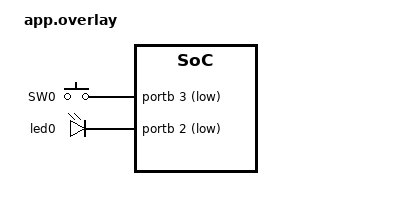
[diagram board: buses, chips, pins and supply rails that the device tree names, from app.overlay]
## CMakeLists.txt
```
cmake_minimum_required(VERSION 3.20.0)
find_package(Zephyr REQUIRED HINTS $ENV{ZEPHYR_BASE})
project(pic32cm_pl10_blinky_shell)
target_sources(app PRIVATE src/main.c src/led_ctrl.c src/pl10_adc.c src/cmd_parser.c src/fault.c src/diag.c src/button.c src/load.c src/standby.c src/sleeptest.c src/lpsleep.c)

# Declare the "cmd" console-command registry as an iterable ROM section (see
# app/src/cmd.h and app/cmd_sections.ld). SECTIONS (not ROM_SECTIONS) because
# ITERABLE_SECTION_ROM already places itself into the ROMABLE_REGION.
zephyr_linker_sources(SECTIONS cmd_sections.ld)
```

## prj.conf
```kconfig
CONFIG_GPIO=y
CONFIG_SERIAL=y
CONFIG_CONSOLE=y
CONFIG_UART_CONSOLE=y
CONFIG_LOG=n
CONFIG_REBOOT=y

# We print the boot banner ourselves from cmd_parser.c (with a leading newline,
# so it starts on a fresh line even after a fault-reboot's non-newline-
# terminated dump). Disable Zephyr's built-in banner to avoid printing it twice.
CONFIG_BOOT_BANNER=n

# Lightweight custom command parser instead of the Zephyr shell subsystem: the shell
# took up 39%/38% of RAM/Flash for four trivial LED commands - disproportionate on an
# 8 KB-RAM device. console_getchar() is Zephyr's built-in pull-style, character-by-
# character input API; the app's own cmd_parser.c builds line editing and bash-style
# history recall on top of it (console_getline()'s line-buffered mode can't do
# history - Zephyr's console driver silently drops Up/Down arrow escape sequences).
CONFIG_CONSOLE_SUBSYS=y
CONFIG_CONSOLE_GETCHAR=y

# Fixed kernel baseline trimmed too (ISR stack 2048 B default, main stack 1024 B
# default). ISR_STACK_SIZE is shared globally by ALL interrupts + kernel init -
# riskier to cut than the shell stack, since an overflow is more likely to silently
# corrupt memory than fault cleanly. Verified stable via a pyserial stress test
# (10 ms blink timer running concurrently with 15 rapid "help" calls, the app's
# deepest printk call path) - see RUNBOOK.md Step 7 for details. RAM saved: 52.25% ->
# 33.50%.
CONFIG_ISR_STACK_SIZE=1024
CONFIG_MAIN_STACK_SIZE=512

# Thread introspection for the "threads" console command (k_thread_foreach +
# live stack usage). THREAD_MONITOR maintains the runtime thread list;
# THREAD_NAME stores names (MAX_NAME_LEN trimmed to fit "adc_stream_tid");
# THREAD_STACK_INFO + INIT_STACKS give an accurate used-stack count (INIT_STACKS
# fills each stack with a pattern at init so unused bytes can be counted).
CONFIG_THREAD_MONITOR=y
CONFIG_THREAD_NAME=y
CONFIG_THREAD_MAX_NAME_LEN=16
CONFIG_THREAD_STACK_INFO=y
CONFIG_INIT_STACKS=y

# Software stack-overflow detection. This Cortex-M0+ has no MPU, so the
# hardware option (CONFIG_HW_STACK_PROTECTION) is unavailable; the sentinel is
# the software fallback: a magic value at the bottom of each thread stack,
# checked at every context switch and on ISRs. If a thread overflows past it,
# the kernel raises a fatal error (K_ERR_STACK_CHK_FAIL, reason 2) instead of
# silently corrupting memory. NOTE: the kernel's own thread-naming line goes
# through LOG_ERR and is compiled out by CONFIG_LOG=n above - src/fault.c
# overrides k_sys_fatal_error_handler() to printk the reason + offending thread
# name so the overflow is attributable. Costs 4 B/stack + the periodic checks.
CONFIG_STACK_SENTINEL=y

# Recover automatically from a fatal error (stack overflow, HardFault from a
# bad "mem" address, ...): the kernel prints the full fault dump as usual and
# then reboots, instead of halting forever waiting for a manual reset. Trade-
# off: you can't inspect the halted state with a debugger after the fact - but
# the register/reason dump is already printed before the reset.
CONFIG_RESET_ON_FATAL_ERROR=y

# NOTE on Power Management: the "standby <s>" command (app/src/standby.c) drops
# the SoC into real ~2 uA Standby with direct-register access and REBOOTS on wake -
# it deliberately does NOT use Zephyr's PM subsystem (CONFIG_PM). Mainline Zephyr
# has no PM/power-domain driver for the PL10, and supplying the hooks ourselves
# gave a Standby that reached 2 uA but left the kernel tick dead afterwards (gating
# OSCHF kills the RTC compare the tickless low-power path relies on). So CONFIG_PM
# is intentionally absent; see the header comment in standby.c for the full story.
```

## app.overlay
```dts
/*
 * Application devicetree overlay for the PIC32CM PL10 Curiosity Nano.
 *
 * Zephyr's board support defines only led0 (PB2), not the on-board user switch.
 * The PIC32CM PL10 Curiosity Nano User Guide (DS50004003, section 4.2
 * "Mechanical Switch") puts SW0 on PB03: pressing it pulls the pin to GND, and
 * there is no external pull-up, so it is active-low and needs the MCU's internal
 * pull-up enabled. This overlay adds it as a gpio-keys node with an `sw0` alias;
 * button.c reads it via GPIO_DT_SPEC_GET (no CONFIG_INPUT needed - the node is
 * just data we read with the GPIO API).
 */
#include <zephyr/dt-bindings/gpio/gpio.h>
#include <zephyr/dt-bindings/input/input-event-codes.h>

/ {
	buttons {
		compatible = "gpio-keys";

		sw0: button_0 {
			gpios = <&portb 3 (GPIO_ACTIVE_LOW | GPIO_PULL_UP)>;
			label = "SW0";
			zephyr,code = <INPUT_KEY_0>;
		};
	};

	aliases {
		sw0 = &sw0;
	};
};

/*
 * Fix the LED0 polarity. The board devicetree declares led0 as GPIO_ACTIVE_HIGH,
 * but the on-board LED is wired active-low - the User Guide (section 4.1 "LED")
 * states "Driving the connected I/O line to GND will activate the LED". With the
 * wrong flag every led_ctrl_*() call is inverted (`led on` drives the pin high =
 * LED off), and - importantly for power - `led_ctrl_off()` drove the pin LOW,
 * turning the LED physically ON and sinking ~1 mA through it during `standby`.
 * Overriding the flag here (rather than editing the pinned board file) makes
 * on/off correct and lets the LED actually go dark in Standby.
 */
&led0 {
	gpios = <&portb 2 GPIO_ACTIVE_LOW>;
};
```

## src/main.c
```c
#include "led_ctrl.h"

/*
 * The application is built from self-contained modules that each start their
 * own thread (led_ctrl.c's blink thread, cmd_parser.c's command thread,
 * pl10_adc.c's stream thread). main() only wires up startup policy: bring the
 * LED up and set its default state.
 */
int main(void)
{
    if (led_ctrl_init() != 0) {
        return 0;
    }
    led_ctrl_blink(500);
    return 0;
}
```

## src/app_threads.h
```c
#ifndef APP_THREADS_H_
#define APP_THREADS_H_

/*
 * Central budget/priority table for the application threads.
 *
 * The threads themselves are still defined (K_THREAD_DEFINE) in the module
 * that owns their state - led_ctrl.c, pl10_adc.c, cmd_parser.c - so each
 * module stays self-contained. Only their stack sizes and priorities live
 * here, so every thread budget can be seen and tuned in one place instead of
 * hunting through the modules. For a live view of actual stack usage, run the
 * "threads" console command (see cmd_parser.c).
 */

/*
 * Stack sizes are set with headroom over the measured high-water mark (run
 * the "threads" command to see live usage). The initial 256/320 B for the
 * blink/ADC threads turned out to read 100%/97% used - bumped to 512 so
 * there's real margin, since a Cortex-M0+ overflow corrupts silently (no MPU
 * / no stack sentinel here). Re-check with "threads" after touching a thread's
 * call path (e.g. a deeper driver call, printf format).
 */
#define BLINK_THREAD_STACK_SIZE       352
#define BLINK_THREAD_PRIORITY         7

#define ADC_STREAM_THREAD_STACK_SIZE  352
#define ADC_STREAM_THREAD_PRIORITY    7

#define CMD_THREAD_STACK_SIZE         640
#define CMD_THREAD_PRIORITY           7

#define BUTTON_THREAD_STACK_SIZE      384
#define BUTTON_THREAD_PRIORITY        7

/*
 * The CPU-load generator (load.c, the "load" command). Priority is one *below*
 * the app threads above so it only burns time that would otherwise be idle:
 * the console/blink/ADC/button threads (priority 7) always preempt it, so they
 * stay responsive while the core is held busy. Its stack is tiny - the thread
 * only runs an arithmetic loop and a semaphore take, no printf/driver calls -
 * but re-check with the "threads" command after any change.
 */
#define LOAD_THREAD_STACK_SIZE        320
#define LOAD_THREAD_PRIORITY          8

#endif /* APP_THREADS_H_ */
```

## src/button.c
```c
/*
 * button.c - read the on-board user switch SW0 and expose it as the `button`
 * console command.
 *
 * SW0 is on PB03 (PIC32CM PL10 Curiosity Nano User Guide DS50004003, section 4.2
 * "Mechanical Switch"). Pressing it pulls PB03 to GND, and the board has no
 * external pull-up, so the pin is configured active-low with the MCU's internal
 * pull-up enabled - both flags come from the devicetree node in app/app.overlay
 * (Zephyr's board support defines only led0, not the switch). Because
 * gpio_pin_get_dt() returns the *logical* level, GPIO_ACTIVE_LOW is handled for
 * us: 1 means pressed.
 *
 * Two ways to observe it: the `button` console command reads the current state
 * on demand, and a small background thread (button_tid) watches for edges and
 * prints a message when the button is pressed or released - asynchronously,
 * like pl10_adc.c's stream. GPIO pin interrupts aren't an option here: the
 * PL10's pin-interrupt path needs the EIC (CONFIG_INTC_MCHP_EIC_G1), and this
 * Zephyr revision has no EIC devicetree node for the PL10, so
 * gpio_pin_interrupt_configure() returns -ENOTSUP. Polling every 50 ms is well
 * within a human press and also debounces the switch (contact bounce is far
 * shorter than the poll interval).
 *
 * Self-registered via CMD_REGISTER (like diag.c); the pin is configured lazily
 * on first use (mirrors pl10_adc.c's ensure_adc_ready) so main.c stays
 * untouched.
 */
#include <zephyr/kernel.h>
#include <zephyr/drivers/gpio.h>
#include <errno.h>

#include "app_threads.h"
#include "cmd.h"

#define SW0_NODE DT_ALIAS(sw0)
static const struct gpio_dt_spec sw0 = GPIO_DT_SPEC_GET(SW0_NODE, gpios);

static bool sw0_ready;

static int ensure_sw0_ready(void)
{
    if (sw0_ready) {
        return 0;
    }
    if (!gpio_is_ready_dt(&sw0)) {
        return -ENODEV;
    }

    /* GPIO_INPUT combines with the node's dt_flags (GPIO_ACTIVE_LOW |
     * GPIO_PULL_UP), so the internal pull-up is enabled here. */
    int ret = gpio_pin_configure_dt(&sw0, GPIO_INPUT);
    if (ret != 0) {
        return ret;
    }

    sw0_ready = true;
    return 0;
}

static void button_cmd(int argc, char **argv)
{
    ARG_UNUSED(argc);
    ARG_UNUSED(argv);

    if (ensure_sw0_ready() != 0) {
        printk("button: not available\n");
        return;
    }

    int val = gpio_pin_get_dt(&sw0);
    if (val < 0) {
        printk("button: read error %d\n", val);
        return;
    }

    printk("button: %s\n", val ? "pressed" : "released");
}
CMD_REGISTER(button, "button", button_cmd, "button          - read the SW0 user button");

/* --- background press/release notifier ---------------------------------- */

#define BUTTON_POLL_MS 50

static void button_thread_entry(void *p1, void *p2, void *p3)
{
    ARG_UNUSED(p1);
    ARG_UNUSED(p2);
    ARG_UNUSED(p3);

    if (ensure_sw0_ready() != 0) {
        return; /* pin unavailable - nothing to watch */
    }

    /* Seed with the current level so we only report actual changes. */
    int prev = gpio_pin_get_dt(&sw0);

    while (1) {
        k_sleep(K_MSEC(BUTTON_POLL_MS));

        int cur = gpio_pin_get_dt(&sw0);
        if (cur < 0 || cur == prev) {
            continue;
        }

        printk("button: %s\n", cur ? "pressed" : "released");
        prev = cur;
    }
}
K_THREAD_DEFINE(button_tid, BUTTON_THREAD_STACK_SIZE, button_thread_entry, NULL, NULL, NULL,
        BUTTON_THREAD_PRIORITY, 0, 0);
```

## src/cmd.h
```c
#ifndef CMD_H_
#define CMD_H_

#include <zephyr/sys/iterable_sections.h>

/*
 * Console command registry. Each feature module registers its own top-level
 * command with CMD_REGISTER(); the parser (cmd_parser.c) only tokenizes the
 * line, looks up argv[0] in this registry and dispatches - it has no knowledge
 * of led/adc/etc. The registration table lives in a custom iterable ROM
 * section ("cmd"), built at link time, so it costs ~0 RAM (same mechanism as
 * Zephyr's SHELL_CMD_REGISTER, without the shell subsystem's overhead). The
 * linker section is declared in app/cmd_sections.ld (wired in via
 * zephyr_linker_sources() in app/CMakeLists.txt).
 */

/* Handler for one command. argv[0] is the command name; argv[1..argc-1] are
 * its arguments. Handlers print their own output/usage (hence void). */
typedef void (*cmd_fn_t)(int argc, char **argv);

struct cmd {
	const char *name; /* first token to match, e.g. "led" */
	cmd_fn_t fn;      /* dispatched handler */
	const char *help; /* one-line help, printed by the "help" command */
};

/*
 * Register a command. `id` must be unique within its source file (it forms the
 * variable name). `const` is mandatory: it places the entry in the ROM "cmd"
 * section rather than RAM. The entry is not referenced by name anywhere, so the
 * KEEP() in the linker fragment is what stops the linker from garbage-collecting
 * it.
 */
#define CMD_REGISTER(id, name_, fn_, help_)                       \
	static const STRUCT_SECTION_ITERABLE(cmd, _cmd_##id) = {  \
		.name = (name_),                                  \
		.fn = (fn_),                                      \
		.help = (help_),                                  \
	}

#endif /* CMD_H_ */
```

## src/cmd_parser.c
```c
#include <zephyr/kernel.h>
#include <zephyr/console/console.h>
#include <zephyr/version.h>
#include <ctype.h>
#include <stdbool.h>
#include <string.h>

#include "app_threads.h"
#include "cmd.h"

/*
 * Generic console front-end: a hand-rolled line editor (with bash-style Up/Down
 * history) over console_getchar(), plus a tokenizer that dispatches each line
 * to the command registry (cmd.h). This module knows nothing about led/adc/etc.
 * - every command lives in its owning module and self-registers via
 * CMD_REGISTER(); adding a command never touches this file. Only "help" is
 * built in here, since it is intrinsic to the registry.
 */

/*
 * We print the boot banner ourselves (CONFIG_BOOT_BANNER=n) so it can start
 * with a leading newline - Zephyr's own banner has no leading '\n', so after
 * a fault-triggered reboot it glued onto the tail of the (non-newline-
 * terminated) fault dump. Version string derived exactly as Zephyr's
 * boot_banner.c does. */
#if defined(BUILD_VERSION) && !IS_EMPTY(BUILD_VERSION)
#define ZEPHYR_VERSION_STR STRINGIFY(BUILD_VERSION)
#else
#define ZEPHYR_VERSION_STR KERNEL_VERSION_STRING
#endif

#define PROMPT "pl10:~$ "

#define CMD_LINE_MAX_LEN 32
#define CMD_HISTORY_DEPTH 5
#define CMD_MAX_ARGS 4 /* deepest: "adc stream start" / "mem <addr> <n>" = 3 */

#define KEY_BS 0x08
#define KEY_DEL 0x7f
#define KEY_ESC 0x1b
#define KEY_CSI '['
#define KEY_UP 'A'
#define KEY_DOWN 'B'

/* Split `line` into argv[] in place (spaces overwritten with '\0'). Returns
 * argc; extra tokens beyond `max` are left attached to the last argv entry. */
static int tokenize(char *line, char **argv, int max)
{
    int argc = 0;

    while (*line != '\0' && argc < max) {
        while (*line == ' ') {
            *line++ = '\0';
        }
        if (*line == '\0') {
            break;
        }
        argv[argc++] = line;
        while (*line != '\0' && *line != ' ') {
            line++;
        }
    }
    return argc;
}

static void handle_line(char *line)
{
    char *argv[CMD_MAX_ARGS];
    int argc = tokenize(line, argv, CMD_MAX_ARGS);

    if (argc == 0) {
        return; /* empty line */
    }

    STRUCT_SECTION_FOREACH(cmd, c) {
        if (strcmp(argv[0], c->name) == 0) {
            c->fn(argc, argv);
            return;
        }
    }
    printk("unknown command: %s\n", argv[0]);
}

/* "help" is built in here: it iterates the command registry and prints each
 * entry's one-line help. Registration order is link order (not sorted). */
static void help_cmd(int argc, char **argv)
{
    ARG_UNUSED(argc);
    ARG_UNUSED(argv);

    printk("Available commands:\n");
    STRUCT_SECTION_FOREACH(cmd, c) {
        printk("  %s\n", c->help);
    }
    printk("  (Up/Down arrow recalls the last %u commands)\n", CMD_HISTORY_DEPTH);
}
CMD_REGISTER(help, "help", help_cmd, "help            - show this help");

/* Ring buffer of the last CMD_HISTORY_DEPTH submitted lines, oldest first. */
static char cmd_history[CMD_HISTORY_DEPTH][CMD_LINE_MAX_LEN];
static uint8_t cmd_history_count;
static uint8_t cmd_history_next;

/* Map a chronological position (0 = oldest kept, cmd_history_count - 1 =
 * newest) to its physical ring-buffer slot. */
static uint8_t cmd_history_index(uint8_t pos)
{
    uint8_t start = (cmd_history_count == CMD_HISTORY_DEPTH) ? cmd_history_next : 0;
    return (start + pos) % CMD_HISTORY_DEPTH;
}

static void cmd_history_add(const char *line)
{
    if (*line == '\0') {
        return;
    }

    strncpy(cmd_history[cmd_history_next], line, CMD_LINE_MAX_LEN - 1);
    cmd_history[cmd_history_next][CMD_LINE_MAX_LEN - 1] = '\0';

    cmd_history_next = (cmd_history_next + 1) % CMD_HISTORY_DEPTH;
    if (cmd_history_count < CMD_HISTORY_DEPTH) {
        cmd_history_count++;
    }
}

/*
 * printk() and console_putchar() are two independent output paths on top of
 * the same UART (printk goes straight through uart_console.c's synchronous
 * uart_poll_out(); console_putchar() goes through console_getchar()'s own
 * buffered, interrupt-driven tty layer). Mixing them reorders/drops bytes on
 * the wire, so every echo/redraw byte here goes through printk("%c", ...)
 * instead of console_putchar() - one single output path throughout.
 */
static void echo_char(char c)
{
    printk("%c", c);
}

static void echo_backspace(void)
{
    printk("\b \b");
}

/* Erase `len` already-echoed characters left of the cursor and reprint
 * `text` (`len_new` chars) in their place - works on any plain terminal,
 * no ANSI cursor-positioning required. */
static void redraw_line(size_t len, const char *text, size_t len_new)
{
    for (size_t i = 0; i < len; i++) {
        echo_backspace();
    }
    for (size_t i = 0; i < len_new; i++) {
        echo_char(text[i]);
    }
}

/* Hand-rolled line editor: console_getline() has no Up/Down history recall
 * (Zephyr's console driver silently drops those escape sequences - see
 * conversation history), so this reads character-by-character via
 * console_getchar() instead and implements just enough editing for this
 * app: end-of-line backspace, and bash-style history browsing. No mid-line
 * cursor movement (Left/Right arrows) - out of scope for this minimal
 * parser, same reasoning that kept the Zephyr shell out of this project.
 */
static size_t cmd_read_line(char *buf, size_t buf_size)
{
    /* Persists across calls: a "\r\n" pair spans two console_getchar() calls
     * that can land in two different cmd_read_line() invocations (the '\r'
     * ends this line; the '\n' arrives right at the start of the next
     * read). Remembering the last byte lets that trailing '\n' be swallowed
     * instead of being misread as an Enter on an empty line - same trick
     * Zephyr's own uart_console_isr() uses for CONFIG_CONSOLE_GETLINE. */
    static uint8_t last_char;

    size_t len = 0;
    uint8_t history_pos = cmd_history_count; /* one past newest = "not browsing" */

    buf[0] = '\0';

    while (1) {
        int c = console_getchar();

        if (c < 0) {
            continue;
        }

        if (c == '\n' && last_char == '\r') {
            last_char = (uint8_t)c;
            continue;
        }
        last_char = (uint8_t)c;

        if (c == '\r' || c == '\n') {
            printk("\n");
            buf[len] = '\0';
            return len;
        }

        if (c == KEY_BS || c == KEY_DEL) {
            if (len > 0) {
                len--;
                echo_backspace();
            }
            continue;
        }

        if (c == KEY_ESC) {
            if (console_getchar() != KEY_CSI) {
                continue;
            }
            int key = console_getchar();

            if (key != KEY_UP && key != KEY_DOWN) {
                continue; /* unsupported escape sequence - ignore */
            }

            uint8_t new_pos = history_pos;
            if (key == KEY_UP && history_pos > 0) {
                new_pos = history_pos - 1;
            } else if (key == KEY_DOWN && history_pos < cmd_history_count) {
                new_pos = history_pos + 1;
            }
            if (new_pos == history_pos) {
                continue;
            }
            history_pos = new_pos;

            size_t old_len = len;
            if (history_pos == cmd_history_count) {
                len = 0;
            } else {
                len = strlen(cmd_history[cmd_history_index(history_pos)]);
                memcpy(buf, cmd_history[cmd_history_index(history_pos)], len);
            }
            buf[len] = '\0';
            redraw_line(old_len, buf, len);
            continue;
        }

        if (isprint(c) != 0 && len + 1 < buf_size) {
            buf[len++] = (char)c;
            echo_char((char)c);
        }
    }
}

static void cmd_thread_entry(void *p1, void *p2, void *p3)
{
    console_init();

    static char line[CMD_LINE_MAX_LEN];

    /* Leading '\n' (printk emits it as CR+LF) so the banner always starts on
     * a fresh line, even right after a non-newline-terminated fault dump. */
    printk("\n*** Booting Zephyr OS build " ZEPHYR_VERSION_STR " ***\n"
           "PIC32CM PL10 Blinky - built " __DATE__ " " __TIME__ "\n");
    printk(PROMPT);
    while (1) {
        cmd_read_line(line, sizeof(line));
        cmd_history_add(line);
        handle_line(line);
        printk(PROMPT);
    }
}
K_THREAD_DEFINE(cmd_tid, CMD_THREAD_STACK_SIZE, cmd_thread_entry, NULL, NULL, NULL,
        CMD_THREAD_PRIORITY, 0, 0);
```

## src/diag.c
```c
/*
 * diag.c - system / diagnostic console commands: reset, threads, mem.
 *
 * These are not tied to any feature peripheral, so they live here (rather than
 * in the parser) and self-register with the command registry (cmd.h), keeping
 * cmd_parser.c free of any command-specific knowledge.
 */
#include <zephyr/kernel.h>
#include <zephyr/sys/reboot.h>
#include <stdlib.h>

#include "cmd.h"

static void reset_cmd(int argc, char **argv)
{
    ARG_UNUSED(argc);
    ARG_UNUSED(argv);

    printk("resetting...\n");
    sys_reboot(SYS_REBOOT_COLD);
}
CMD_REGISTER(reset, "reset", reset_cmd, "reset           - reboot the board");

/* k_thread_foreach() callback: print one thread's name, priority, and live
 * stack usage. Needs CONFIG_THREAD_MONITOR (thread list), THREAD_NAME
 * (names), THREAD_STACK_INFO + INIT_STACKS (accurate used-stack count) -
 * see prj.conf. */
static void thread_info_cb(const struct k_thread *thread, void *user_data)
{
    ARG_UNUSED(user_data);

    size_t unused = 0;
    (void)k_thread_stack_space_get(thread, &unused);

    size_t total = thread->stack_info.size;
    const char *name = k_thread_name_get((k_tid_t)thread);

    printk("  %-14s prio %2d  stack %u/%u B\n",
           (name != NULL && name[0] != '\0') ? name : "?",
           k_thread_priority_get((k_tid_t)thread),
           (unsigned int)(total - unused), (unsigned int)total);
}

static void threads_cmd(int argc, char **argv)
{
    ARG_UNUSED(argc);
    ARG_UNUSED(argv);

    printk("Threads (used/total stack):\n");
    k_thread_foreach(thread_info_cb, NULL);
}
CMD_REGISTER(threads, "threads", threads_cmd, "threads         - list threads with live stack usage");

/* Raw memory hex-dump. Deliberately does NO address validation - reading an
 * unmapped, peripheral, or misaligned address will bus-fault (HardFault) on
 * this MPU-less Cortex-M0+, which is intentional here: it lets you provoke and
 * study faults (pairs with CONFIG_STACK_SENTINEL / the fatal-error handler).
 * For a normal dump use a valid RAM (0x20000000) or flash (0x0c000000)
 * address. `volatile` so the read actually happens even if the value is
 * unused (a faulting access must not be optimized away). */
static void mem_cmd(int argc, char **argv)
{
    if (argc < 2) {
        printk("usage: mem <hex-addr> [count]\n");
        return;
    }

    uint32_t addr = (uint32_t)strtoul(argv[1], NULL, 16);
    uint32_t count = (argc >= 3) ? (uint32_t)strtoul(argv[2], NULL, 0) : 64;

    if (count == 0) {
        count = 64;
    }

    const volatile uint8_t *p = (const volatile uint8_t *)addr;

    for (uint32_t i = 0; i < count; i += 16) {
        printk("%08x: ", addr + i);

        for (uint32_t j = 0; j < 16; j++) {
            if (i + j < count) {
                printk("%02x ", p[i + j]);
            } else {
                printk("   ");
            }
        }

        printk(" |");
        for (uint32_t j = 0; j < 16 && i + j < count; j++) {
            uint8_t c = p[i + j];
            printk("%c", (c >= 0x20 && c < 0x7f) ? c : '.');
        }
        printk("|\n");
    }
}
CMD_REGISTER(mem, "mem", mem_cmd, "mem <addr> [n]  - hex-dump n bytes at hex <addr> (no bounds check, can fault)");
```

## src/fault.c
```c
/*
 * fault.c - fatal-error handler that names the offending thread, then reboots.
 *
 * With CONFIG_LOG=n the kernel's own ">>> ZEPHYR FATAL ERROR N" / "Current
 * thread: ..." lines (printed by z_fatal_error() via LOG_ERR) are compiled
 * out, so the only thing on the console is the ARM register ESF dump - which
 * does NOT say which thread faulted. In particular a CONFIG_STACK_SENTINEL
 * stack-overflow (K_ERR_STACK_CHK_FAIL) is then indistinguishable, from the
 * raw dump alone, from a random HardFault, and can't be attributed to a thread.
 *
 * We override the __weak k_sys_fatal_error_handler() (kernel/fatal.c) to print
 * that missing context ourselves via printk() - which is synchronous and works
 * with logging disabled - so an overflow is immediately attributable to a
 * thread by name. It runs AFTER the arch register dump, right before the reset.
 *
 * Reboot behaviour mirrors the default handler and stays governed by
 * CONFIG_RESET_ON_FATAL_ERROR (reset vs. halt), so removing this file falls
 * back to the identical reboot, just without the thread line.
 */
#include <zephyr/kernel.h>
#include <zephyr/fatal.h>
#include <zephyr/sys/printk.h>
#include <zephyr/sys/reboot.h>

static const char *reason_str(unsigned int reason)
{
	switch (reason) {
	case K_ERR_CPU_EXCEPTION:  return "CPU exception";
	case K_ERR_SPURIOUS_IRQ:   return "unhandled interrupt";
	case K_ERR_STACK_CHK_FAIL: return "stack overflow (sentinel corruption)";
	case K_ERR_KERNEL_OOPS:    return "kernel oops";
	case K_ERR_KERNEL_PANIC:   return "kernel panic";
	default:                   return "unknown error";
	}
}

void k_sys_fatal_error_handler(unsigned int reason, const struct arch_esf *esf)
{
	ARG_UNUSED(esf);

	struct k_thread *cur = k_current_get();
	const char *name = k_thread_name_get(cur);

	printk("\n*** FATAL ERROR %u: %s ***\n", reason, reason_str(reason));
	printk("*** in thread: %s (%p) ***\n",
	       (name != NULL && name[0] != '\0') ? name : "unknown", cur);

#if IS_ENABLED(CONFIG_RESET_ON_FATAL_ERROR)
	sys_reboot(SYS_REBOOT_WARM);
#else
	arch_system_halt(reason);
#endif
	CODE_UNREACHABLE;
}
```

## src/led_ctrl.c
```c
#include <zephyr/kernel.h>
#include <zephyr/drivers/gpio.h>
#include <errno.h>
#include <stdlib.h>
#include <string.h>

#include "app_threads.h"
#include "cmd.h"
#include "led_ctrl.h"

#define LED0_NODE DT_ALIAS(led0)
static const struct gpio_dt_spec led = GPIO_DT_SPEC_GET(LED0_NODE, gpios);

/* Blink interval in ms; 0 = no automatic blinking */
static volatile uint32_t blink_ms;

/* Live toggle counter: increments on every completed blink. A "liveness beacon"
 * for the blink thread - if it keeps climbing, the thread is running and its
 * k_sleep timing works. Handy to confirm the kernel clock survived a Standby nap
 * (query with "led count" before/after: it must resume climbing on wake). */
static volatile uint32_t blink_count;

static void blink_thread_entry(void *p1, void *p2, void *p3)
{
    while (1) {
        uint32_t ms = blink_ms;

        if (ms == 0) {
            k_sleep(K_FOREVER);
            continue;
        }

        /* Only toggle if the sleep ran to completion - if led_ctrl_blink()
         * woke us up early (rate changed, or blinking stopped), re-read
         * blink_ms and start over instead of toggling on stale settings. */
        if (k_sleep(K_MSEC(ms)) == 0) {
            gpio_pin_toggle_dt(&led);
            blink_count++;
        }
    }
}
K_THREAD_DEFINE(blink_tid, BLINK_THREAD_STACK_SIZE, blink_thread_entry, NULL, NULL, NULL,
        BLINK_THREAD_PRIORITY, 0, 0);

void led_ctrl_blink(uint32_t ms)
{
    blink_ms = ms;
    k_wakeup(blink_tid);
}

void led_ctrl_on(void)
{
    led_ctrl_blink(0);
    gpio_pin_set_dt(&led, 1);
}

void led_ctrl_off(void)
{
    led_ctrl_blink(0);
    gpio_pin_set_dt(&led, 0);
}

void led_ctrl_toggle(void)
{
    led_ctrl_blink(0);
    gpio_pin_toggle_dt(&led);
}

int led_ctrl_init(void)
{
    if (!gpio_is_ready_dt(&led)) {
        return -ENODEV;
    }
    gpio_pin_configure_dt(&led, GPIO_OUTPUT_ACTIVE);
    return 0;
}

/* --- console command ---------------------------------------------------- */

static void led_cmd(int argc, char **argv)
{
    if (argc == 2 && strcmp(argv[1], "on") == 0) {
        led_ctrl_on();
        printk("led on\n");
    } else if (argc == 2 && strcmp(argv[1], "off") == 0) {
        led_ctrl_off();
        printk("led off\n");
    } else if (argc == 2 && strcmp(argv[1], "toggle") == 0) {
        led_ctrl_toggle();
        printk("led toggled\n");
    } else if (argc == 3 && strcmp(argv[1], "blink") == 0) {
        uint32_t ms = (uint32_t)strtoul(argv[2], NULL, 10);
        led_ctrl_blink(ms);
        printk("led blink %u ms\n", ms);
    } else if (argc == 2 && strcmp(argv[1], "count") == 0) {
        printk("led toggles: %u\n", blink_count);
    } else {
        printk("usage: led on|off|toggle|blink <ms>|count\n");
    }
}
CMD_REGISTER(led, "led", led_cmd, "led on|off|toggle|blink <ms>|count - LED control");
```

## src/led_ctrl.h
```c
#ifndef LED_CTRL_H_
#define LED_CTRL_H_

#include <stdint.h>

/* LED0 hardware ownership (GPIO + the dedicated blink thread) lives in
 * led_ctrl.c; this is the only interface the rest of the app uses. */

/* Configure the LED GPIO. Returns 0 on success, negative errno on failure
 * (LED device not ready). Call once at startup before any other function. */
int led_ctrl_init(void);

void led_ctrl_on(void);
void led_ctrl_off(void);
void led_ctrl_toggle(void);

/* Blink every ms milliseconds; 0 stops blinking. */
void led_ctrl_blink(uint32_t ms);

#endif /* LED_CTRL_H_ */
```

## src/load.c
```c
/*
 * load.c - a CPU-load generator exposed as the `load` console command, for
 * measuring the difference between the idle (WFI) and active current draw of
 * the PL10.
 *
 * Normally this firmware is almost always asleep: every thread does a little
 * work and then k_sleep()s, so the idle thread runs and executes WFI, halting
 * the core (see DEEPDIVE.md "Idle, WFI, and CPU load"). The datasheet puts that
 * Idle current at ~1.2 mA vs. ~5.2 mA for a 100%-busy core, so keeping the CPU
 * busy should raise the board's current draw by ~4 mA - visible in mA
 * resolution even on the USB port (where the nEDBG debugger + LED dominate the
 * absolute figure, but the *delta* from load on/off still shows).
 *
 * `load on` starts a busy loop that prevents the core from ever reaching WFI;
 * `load off` stops it. The generator runs in its own thread (load_tid) at a
 * priority *below* the application threads (LOAD_THREAD_PRIORITY, see
 * app_threads.h): it therefore only consumes time that would otherwise be idle,
 * so the console, blink, ADC and button threads (all priority 7) still preempt
 * it instantly and stay fully responsive. When load is off the thread blocks on
 * a semaphore and consumes nothing, so the idle thread's WFI returns.
 *
 * Self-registered via CMD_REGISTER, like the other feature modules.
 */
#include <zephyr/kernel.h>
#include <string.h>

#include "app_threads.h"
#include "cmd.h"

/* Set when load is active. volatile so the busy loop re-reads it every
 * iteration (so `load off` takes effect at once, and the loop can't be
 * optimized away). */
static volatile bool load_on;

/* Sink for the busy-loop result. volatile so the compiler can't discard the
 * computation as dead code. */
static volatile uint32_t load_sink;

/* Released by `load on` to wake the generator thread out of its idle block. */
static K_SEM_DEFINE(load_sem, 0, 1);

static void load_cmd(int argc, char **argv)
{
    if (argc < 2) {
        printk("load: %s\n", load_on ? "on" : "off");
        printk("usage: load on|off\n");
        return;
    }

    if (strcmp(argv[1], "on") == 0) {
        if (!load_on) {
            load_on = true;
            k_sem_give(&load_sem); /* unblock the generator thread */
        }
        printk("load: on - CPU held busy (no WFI); expect ~4 mA higher draw\n");
        printk("load: tip - 'led off' to stop the blink for a cleaner baseline\n");
    } else if (strcmp(argv[1], "off") == 0) {
        load_on = false; /* generator returns to its semaphore block */
        printk("load: off - core back to WFI idle\n");
    } else {
        printk("usage: load on|off\n");
    }
}
CMD_REGISTER(load, "load", load_cmd, "load on|off     - burn CPU cycles to raise current draw");

/* --- CPU-load generator thread ------------------------------------------ */

static void load_thread_entry(void *p1, void *p2, void *p3)
{
    ARG_UNUSED(p1);
    ARG_UNUSED(p2);
    ARG_UNUSED(p3);

    uint32_t acc = 1;

    while (1) {
        /* Idle: block until `load on` gives the semaphore. Consumes no CPU,
         * so the kernel idle thread runs and the core reaches WFI. */
        k_sem_take(&load_sem, K_FOREVER);

        /* Busy: a self-feeding LCG recurrence (can't be constant-folded) that
         * runs flat out until `load off` clears the flag. Being lower priority
         * than the app threads, this only replaces idle time - the console
         * still preempts it to handle `load off`. */
        while (load_on) {
            acc = acc * 1664525u + 1013904223u;
            load_sink = acc;
        }
    }
}
K_THREAD_DEFINE(load_tid, LOAD_THREAD_STACK_SIZE, load_thread_entry, NULL, NULL, NULL,
        LOAD_THREAD_PRIORITY, 0, 0);
```

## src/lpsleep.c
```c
/*
 * lpsleep.c - "lpsleep <s>": run-time deep low-power sleep that implements ALL of
 * the datasheet's ~2 uA Standby conditions, with resume in place (no reboot).
 *
 * THE JOURNEY (why this is the shape it is)
 * The shipped `standby` never drops below the ~15.8 mA debugger-halt level. We
 * chased why through a long measured investigation (see strommessung.md); the two
 * findings that matter:
 *
 * 1. ROOT CAUSE - OSCHF was never gateable. The SoC devicetree configures OSCHF
 *    at OSCHFCTRL.ONDEMAND=0 (free-running), so it runs forever no matter what -
 *    no sleep mode and no clock trick can stop it. Confirmed with the `oschftest`
 *    probe: OSCHFRDY stays 1 with no requester, and only flips to 0 once we set
 *    ONDEMAND=1. This is why standby/sbq/genoff all stuck at the same floor.
 *
 * 2. So lpsleep does the full recipe: set OSCHF ONDEMAND=1, move GCLK0 (the CPU
 *    clock) off OSCHF onto the internal 32.768 kHz OSC32K (independent of OSCHF and
 *    the RTC's clock), which lets OSCHF stop AND engages the ULP regulator
 *    (SUPC.VREG.RUNSTDBY=0 switches LDO->ULP when running on 32 kHz). It then
 *    enters STANDBY, masks all APB clocks except PM/MCLK/clock-controllers/RTC
 *    (AHBMASK is already 0x3FF), and disables every pin input buffer - i.e. every
 *    condition in datasheet Table 37-8. The free-running RTC compare (on OSC32K)
 *    wakes it; it switches GCLK0 back to OSCHF, restores everything, and continues.
 *
 * MEASURED OUTCOME (POWER-Z KM003C, USB rail): even with all of the above, the
 * board stays at ~15.83 mA - identical to standby. OSCHF turned out to be only
 * ~0.44 mA; the rest of the halt->reset-floor gap is the on-board nEDBG debugger,
 * a fixed board floor firmware cannot touch. Whether the *target* reaches the
 * datasheet ~2 uA can only be seen by metering the isolated target rail (cut J201);
 * from USB, ~15.8 mA is the wall. The target is now configured correctly for it.
 *
 * CAVEAT: interrupts are locked across the nap and the tickless SysTick is not
 * handed the elapsed time, so the Zephyr kernel tick does not advance - k_sleep
 * threads (blink) freeze on wake though the console stays alive. Experimental /
 * measurement command; a real resume-in-place PM driver would fix the tick.
 */
#include <zephyr/kernel.h>
#include <zephyr/irq.h>
#include <stdlib.h>

#include <pic32cm6408pl10048.h>

#include "cmd.h"
#include "led_ctrl.h"
#include "pl10_adc.h"

#define OSC32K_HZ 32768U       /* nominal OSC32K rate (RC, approximate) */
#define LPSLEEP_MAX_SEC 600U

/* Save every pin's config and disable its input buffer (INEN) - the datasheet
 * "I/Os in inactive input mode" condition; stops crowbar current on any floating
 * input. Fully restored on wake so the console/button/LED work again. */
static uint8_t pincfg_save[2][32];

static void io_quiesce(void)
{
    for (int g = 0; g < 2; g++) {
        for (int p = 0; p < 32; p++) {
            pincfg_save[g][p] = PORT_REGS->GROUP[g].PORT_PINCFG[p];
            PORT_REGS->GROUP[g].PORT_PINCFG[p] &= (uint8_t)~PORT_PINCFG_INEN_Msk;
        }
    }
}

static void io_restore(void)
{
    for (int g = 0; g < 2; g++) {
        for (int p = 0; p < 32; p++) {
            PORT_REGS->GROUP[g].PORT_PINCFG[p] = pincfg_save[g][p];
        }
    }
}

static void gclk0_set_src(uint32_t src_val)
{
    uint32_t g = GCLK_REGS->GCLK_GENCTRL[0];
    g = (g & ~GCLK_GENCTRL_SRC_Msk) | GCLK_GENCTRL_SRC(src_val);
    GCLK_REGS->GCLK_GENCTRL[0] = g;
    while (GCLK_REGS->GCLK_SYNCBUSY & GCLK_SYNCBUSY_GENCTRL0_Msk) {
    }
}

/* RTC MODE0 32-bit counter on OSC32K (32.768 kHz), one-shot compare at `target`
 * counts. Enabling the RTC generates the OSC32K clock request that starts it. */
static void rtc_start_compare(uint32_t target)
{
    MCLK_REGS->MCLK_APBAMASK |= MCLK_APBAMASK_RTC_Msk;
    OSC32KCTRL_REGS->OSC32KCTRL_RTCCTRL = OSC32KCTRL_RTCCTRL_RTCSEL_OSC32K;

    RTC_REGS->MODE0.RTC_CTRLA = RTC_MODE0_CTRLA_SWRST_Msk;
    while (RTC_REGS->MODE0.RTC_SYNCBUSY & RTC_MODE0_SYNCBUSY_SWRST_Msk) {
    }

    RTC_REGS->MODE0.RTC_CTRLA = RTC_MODE0_CTRLA_MODE_COUNT32 | RTC_MODE0_CTRLA_PRESCALER_DIV1;

    RTC_REGS->MODE0.RTC_COMP = target;
    while (RTC_REGS->MODE0.RTC_SYNCBUSY & RTC_MODE0_SYNCBUSY_COMP0_Msk) {
    }

    RTC_REGS->MODE0.RTC_INTFLAG = RTC_MODE0_INTFLAG_CMP0_Msk;
    RTC_REGS->MODE0.RTC_INTENSET = RTC_MODE0_INTENSET_CMP0_Msk;

    RTC_REGS->MODE0.RTC_CTRLA |= RTC_MODE0_CTRLA_ENABLE_Msk;
    while (RTC_REGS->MODE0.RTC_SYNCBUSY & RTC_MODE0_SYNCBUSY_ENABLE_Msk) {
    }
}

static void rtc_stop(void)
{
    RTC_REGS->MODE0.RTC_INTENCLR = RTC_MODE0_INTENCLR_CMP0_Msk;
    RTC_REGS->MODE0.RTC_CTRLA &= (uint16_t)~RTC_MODE0_CTRLA_ENABLE_Msk;
    while (RTC_REGS->MODE0.RTC_SYNCBUSY & RTC_MODE0_SYNCBUSY_ENABLE_Msk) {
    }
    /* RTC disabled -> its OSC32K request drops -> OSC32K (ONDEMAND) stops. */
}

static void lpsleep_cmd(int argc, char **argv)
{
    if (argc != 2) {
        printk("usage: lpsleep <seconds> (1-%u)\n", LPSLEEP_MAX_SEC);
        return;
    }
    int seconds = atoi(argv[1]);
    if (seconds < 1 || seconds > (int)LPSLEEP_MAX_SEC) {
        printk("lpsleep: seconds must be 1-%u\n", LPSLEEP_MAX_SEC);
        return;
    }

    printk("lpsleep: core -> OSC32K, OSCHF off, RTC wake after ~%d s, then resume...\n",
           seconds);
    led_ctrl_off();
    pl10_adc_disable();
    k_msleep(50); /* let the console drain at full speed first */

    uint32_t target = (uint32_t)seconds * OSC32K_HZ;

    /* Lock interrupts so only our loop runs (on Cortex-M0+ PRIMASK does not block
     * WFI wake-up, so the RTC still wakes us; we poll its flag, no ISR). SysTick is
     * left running - we do NOT disable it, so the kernel's tick timer stays intact
     * across the nap (disabling it is what froze the scheduler on wake). */
    NVIC_ClearPendingIRQ(RTC_IRQn);
    NVIC_EnableIRQ(RTC_IRQn);
    unsigned int key = irq_lock();

    rtc_start_compare(target);
    while (!(OSC32KCTRL_REGS->OSC32KCTRL_STATUS & OSC32KCTRL_STATUS_OSC32KRDY_Msk)) {
    }

    /* CRITICAL: the boot/DT config leaves OSCHF at ONDEMAND=0 (free-running), so it
     * never stops even with no requester. Set ONDEMAND=1 so it becomes request-gated;
     * only then does removing GCLK0 below actually switch it off. */
    uint32_t oschfctrl_save = OSCCTRL_REGS->OSCCTRL_OSCHFCTRL;
    OSCCTRL_REGS->OSCCTRL_OSCHFCTRL = oschfctrl_save | OSCCTRL_OSCHFCTRL_ONDEMAND_Msk;

    /* Move the CPU off OSCHF -> OSCHF loses its last requester. Keep GCLK0 running
     * in standby (RUNSTDBY) so the core clock and the OSC32K request survive the
     * nap (the RTC, clocked by OSC32K, then keeps counting to wake us). */
    gclk0_set_src(GCLK_GENCTRL_SRC_OSC32K_Val);
    GCLK_REGS->GCLK_GENCTRL[0] |= GCLK_GENCTRL_RUNSTDBY_Msk;
    while (GCLK_REGS->GCLK_SYNCBUSY & GCLK_SYNCBUSY_GENCTRL0_Msk) {
    }

    /* Enter STANDBY sleep mode. This is the missing piece: only STANDBY actually
     * gates an oscillator that no longer has a requester, so this is what finally
     * stops OSCHF. IDLE alone leaves an unrequested OSCHF running. */
    PM_REGS->PM_SLEEPCFG = PM_SLEEPCFG_SLEEPMODE_STANDBY;
    while ((PM_REGS->PM_SLEEPCFG & PM_SLEEPCFG_SLEEPMODE_Msk) !=
           PM_SLEEPCFG_SLEEPMODE_STANDBY) {
    }
    SCB->SCR |= SCB_SCR_SLEEPDEEP_Msk;

    /* Full-standby clock gating - the datasheet ~2 uA conditions (Table 37-8): mask
     * every APB clock except what we need to wake and resume (PM/MCLK, the clock
     * controllers used by the wake sequence, and the RTC). AHBMASK is already 0x3FF. */
    uint32_t apba_save = MCLK_REGS->MCLK_APBAMASK;
    uint32_t apbb_save = MCLK_REGS->MCLK_APBBMASK;
    uint32_t apbc_save = MCLK_REGS->MCLK_APBCMASK;
    MCLK_REGS->MCLK_APBAMASK = MCLK_APBAMASK_PM_Msk | MCLK_APBAMASK_MCLK_Msk |
                               MCLK_APBAMASK_OSCCTRL_Msk | MCLK_APBAMASK_OSC32KCTRL_Msk |
                               MCLK_APBAMASK_SUPC_Msk | MCLK_APBAMASK_GCLK_Msk |
                               MCLK_APBAMASK_RTC_Msk;
    MCLK_REGS->MCLK_APBBMASK = MCLK_APBBMASK_NVMCTRL_Msk;
    MCLK_REGS->MCLK_APBCMASK = 0U;

    io_quiesce(); /* disable all pin input buffers (last ~2 uA condition) */

    for (;;) {
        if (RTC_REGS->MODE0.RTC_INTFLAG & RTC_MODE0_INTFLAG_CMP0_Msk) {
            break;
        }
        /* Clear a pending SysTick so it doesn't make WFI return immediately (its
         * ISR is masked by irq_lock); the RTC compare is the real wake. */
        SCB->ICSR = SCB_ICSR_PENDSTCLR_Msk;
        __DSB();
        __WFI();
    }
    RTC_REGS->MODE0.RTC_INTFLAG = RTC_MODE0_INTFLAG_CMP0_Msk;

    /* Restore the peripheral clocks and pin configs before touching anything else. */
    MCLK_REGS->MCLK_APBAMASK = apba_save;
    MCLK_REGS->MCLK_APBBMASK = apbb_save;
    MCLK_REGS->MCLK_APBCMASK = apbc_save;
    io_restore();

    /* Leave deep sleep. */
    SCB->SCR &= ~SCB_SCR_SLEEPDEEP_Msk;
    PM_REGS->PM_SLEEPCFG = PM_SLEEPCFG_SLEEPMODE_IDLE;

    /* Back to full speed: re-request OSCHF and wait until it is ready, then drop
     * GCLK0's run-in-standby again. */
    gclk0_set_src(GCLK_GENCTRL_SRC_OSCHF_Val);
    while (!(OSCCTRL_REGS->OSCCTRL_STATUS & OSCCTRL_STATUS_OSCHFRDY_Msk)) {
    }
    GCLK_REGS->GCLK_GENCTRL[0] &= ~GCLK_GENCTRL_RUNSTDBY_Msk;
    while (GCLK_REGS->GCLK_SYNCBUSY & GCLK_SYNCBUSY_GENCTRL0_Msk) {
    }
    OSCCTRL_REGS->OSCCTRL_OSCHFCTRL = oschfctrl_save; /* restore original ONDEMAND state */

    rtc_stop();
    NVIC_DisableIRQ(RTC_IRQn);
    NVIC_ClearPendingIRQ(RTC_IRQn);
    irq_unlock(key);

    printk("lpsleep: resumed on OSCHF.\n");
}
CMD_REGISTER(lpsleep, "lpsleep", lpsleep_cmd,
         "lpsleep <s>     - OSCHF-off sleep on OSC32K, RTC wake, resume-in-place");

/*
 * Diagnostic: does OSCHF actually STOP when GCLK0 no longer sources it? Switch the
 * CPU to OSC32K (OSCHF loses its only requester), spin briefly at 32 kHz, sample
 * OSCCTRL.OSCHFRDY, then switch back and report. No sleep involved - this tests the
 * pure ONDEMAND gating in ACTIVE mode. OSCHFRDY==0 => OSCHF stopped as documented;
 * ==1 => it stays on despite no requester (a boot/latch effect).
 */
static void oschftest_cmd(int argc, char **argv)
{
    ARG_UNUSED(argc);
    ARG_UNUSED(argv);
    k_msleep(30); /* drain console */

    unsigned int key = irq_lock();

    /* Bring OSC32K up by requesting it via the RTC (no interrupt needed here). */
    MCLK_REGS->MCLK_APBAMASK |= MCLK_APBAMASK_RTC_Msk;
    OSC32KCTRL_REGS->OSC32KCTRL_RTCCTRL = OSC32KCTRL_RTCCTRL_RTCSEL_OSC32K;
    RTC_REGS->MODE0.RTC_CTRLA = RTC_MODE0_CTRLA_SWRST_Msk;
    while (RTC_REGS->MODE0.RTC_SYNCBUSY & RTC_MODE0_SYNCBUSY_SWRST_Msk) {
    }
    RTC_REGS->MODE0.RTC_CTRLA = RTC_MODE0_CTRLA_MODE_COUNT32 | RTC_MODE0_CTRLA_PRESCALER_DIV1;
    RTC_REGS->MODE0.RTC_CTRLA |= RTC_MODE0_CTRLA_ENABLE_Msk;
    while (RTC_REGS->MODE0.RTC_SYNCBUSY & RTC_MODE0_SYNCBUSY_ENABLE_Msk) {
    }
    while (!(OSC32KCTRL_REGS->OSC32KCTRL_STATUS & OSC32KCTRL_STATUS_OSC32KRDY_Msk)) {
    }

    uint32_t rdy_before = (OSCCTRL_REGS->OSCCTRL_STATUS & OSCCTRL_STATUS_OSCHFRDY_Msk) ? 1U : 0U;
    uint32_t oschfctrl = OSCCTRL_REGS->OSCCTRL_OSCHFCTRL;

    /* CPU off OSCHF -> OSCHF now has no requester. */
    gclk0_set_src(GCLK_GENCTRL_SRC_OSC32K_Val);
    uint32_t gen0_after = GCLK_REGS->GCLK_GENCTRL[0]; /* confirm SRC really changed */
    for (volatile int i = 0; i < 3000; i++) {
        __NOP();
    }
    uint32_t rdy_unreq = (OSCCTRL_REGS->OSCCTRL_STATUS & OSCCTRL_STATUS_OSCHFRDY_Msk) ? 1U : 0U;

    /* Your idea: re-assert the OSCHF config (ONDEMAND) while it is unrequested, in
     * case the boot state latched it on and it needs re-claiming to become gateable. */
    OSCCTRL_REGS->OSCCTRL_OSCHFCTRL = oschfctrl | OSCCTRL_OSCHFCTRL_ONDEMAND_Msk;
    for (volatile int i = 0; i < 3000; i++) {
        __NOP();
    }
    uint32_t rdy_rearm = (OSCCTRL_REGS->OSCCTRL_STATUS & OSCCTRL_STATUS_OSCHFRDY_Msk) ? 1U : 0U;

    /* back to OSCHF */
    gclk0_set_src(GCLK_GENCTRL_SRC_OSCHF_Val);
    while (!(OSCCTRL_REGS->OSCCTRL_STATUS & OSCCTRL_STATUS_OSCHFRDY_Msk)) {
    }
    rtc_stop();
    irq_unlock(key);

    printk("oschftest: GENCTRL0 after switch=0x%08x (SRC=%u, 3=OSC32K)\n",
           gen0_after, (unsigned)(gen0_after & GCLK_GENCTRL_SRC_Msk));
    printk("oschftest: OSCHFCTRL=0x%08x  OSCHFRDY before=%u unreq=%u re-armed=%u  (0=stopped)\n",
           oschfctrl, rdy_before, rdy_unreq, rdy_rearm);
}
CMD_REGISTER(oschftest, "oschftest", oschftest_cmd,
         "oschftest       - does OSCHF stop when GCLK0 leaves it? (register probe)");
```

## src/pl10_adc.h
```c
#ifndef PL10_ADC_H_
#define PL10_ADC_H_

#include <stdbool.h>

/*
 * Stopgap ADC0 support for the PIC32CM PL10, ported from the bare-metal CMSIS
 * reference in C:\work\Bukarest\3_Mi_CMSIS\. Zephyr has no adc_driver_api/
 * devicetree binding for this SoC's ADC yet (its register map doesn't match
 * either existing in-tree Microchip ADC driver - see conversation history).
 * Replace this with a proper Zephyr driver once upstream support lands.
 *
 * This module owns everything ADC: the low-level register driver plus the
 * application-level read/stream service below. The command parser only ever
 * talks to this interface - it holds no ADC state or hardware knowledge of
 * its own.
 */

/* Period of the background sampling stream, in milliseconds. */
#define PL10_ADC_STREAM_PERIOD_MS 500U

/* One-shot: read the ADC once and print the formatted result. Lazily
 * initializes the hardware on first use. */
void pl10_adc_read_once(void);

/* Start (enable = true) or stop the background sampling stream, which prints
 * one formatted result every PL10_ADC_STREAM_PERIOD_MS. */
void pl10_adc_stream_set(bool enable);

/* Power the ADC down (clear ADC0.ENABLE) so its ~0.9 mA analog bias stops. The
 * low-power/standby path calls this before gating clocks; the next read re-inits
 * lazily. Safe to call when the ADC was never used. */
void pl10_adc_disable(void);

#endif /* PL10_ADC_H_ */
```
